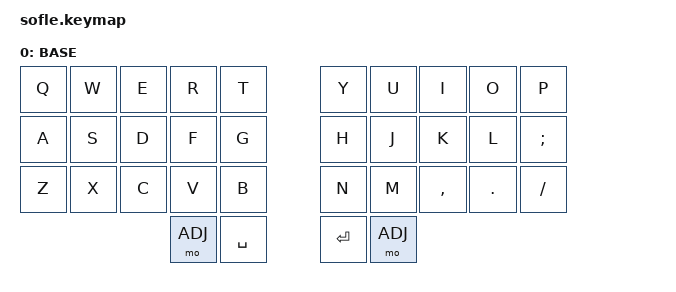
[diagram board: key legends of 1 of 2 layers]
#include <behaviors.dtsi>
#include <dt-bindings/zmk/keys.h>
#include <dt-bindings/zmk/bt.h>

#define BASE 0
#define ADJ  1

/ {
  keymap {
    compatible = "zmk,keymap";

    base_layer {
      label = "BASE";
      bindings = <
        &kp Q &kp W &kp E &kp R &kp T      &kp Y &kp U &kp I &kp O &kp P
        &kp A &kp S &kp D &kp F &kp G      &kp H &kp J &kp K &kp L &kp SEMI
        &kp Z &kp X &kp C &kp V &kp B      &kp N &kp M &kp COMMA &kp DOT &kp SLASH
                   &mo ADJ &kp SPACE      &kp ENTER &mo ADJ
      >;
    };

    adj_layer {
      label = "ADJ";
      bindings = <
        &bt BT_SEL 0 &bt BT_SEL 1 &bt BT_SEL 2 &bt BT_SEL 3 &bt BT_CLR
        &studio_unlock &none &none &none &none
        &none &none &none &none &none
                   &none &none &none &none
      >;
    };
  };
};
